# AM13E23019 register map
Vendor: Texas Instruments; File version: 1.0
CPU: CM33 r0p1, little endian, MPU, FPU, VTOR, 4 interrupt priority bits
Registers are 32-bit, read-write, reset 0x0 unless marked. A register's access mark holds for its fields unless they carry their own. Offsets are from the block's base; [hi:lo] are bit positions; {n}, {i} and the like mark numbered series.

## EQEP0 — EQEP module
Base 0x40448000
Same registers: EQEP1 0x40449000, EQEP2 0x4044A000
0x00 QPOSCNT access not given — Position Counter
0x04 QPOSINIT access not given — Position Counter Init
0x08 QPOSMAX access not given — Maximum Position Count
0x0C QPOSCMP access not given — Position Compare
0x10 QPOSILAT access not given — Index Position Latch
0x14 QPOSSLAT access not given — Strobe Position Latch
0x18 QPOSLAT access not given — Position Latch
0x1C QUTMR access not given — QEP Unit Timer
0x20 QUPRD access not given — QEP Unit Period
0x24 QWDTMR 16-bit access not given — QEP Watchdog Timer
0x26 QWDPRD 16-bit access not given — QEP Watchdog Period
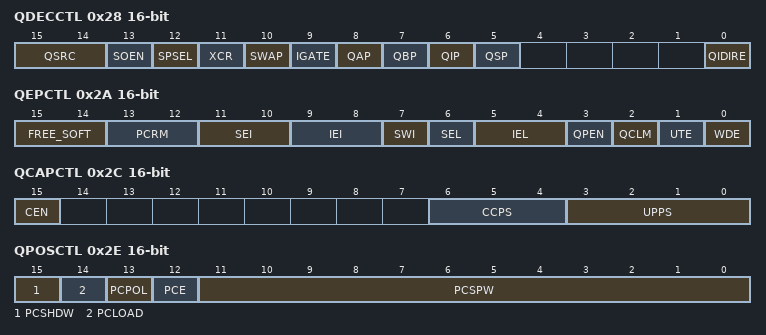
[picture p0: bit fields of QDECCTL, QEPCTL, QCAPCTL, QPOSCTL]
0x28 QDECCTL 16-bit — Quadrature Decoder Control
  [15:14] QSRC — Position-counter source selection
    0=QUAD_COUNT_MODE (Quadrature count mode (QCLK = iCLK, QDIR = iDIR)); 1=DIRECT_COUNT_MODE (Direction-count mode (QCLK = xCLK, QDIR = xDIR)); 2=UP_COUNT_MODE (UP count mode for frequency measurement (QCLK = xCLK, QDIR = 1)); 3=DOWN_COUNT_MODE (DOWN count mode for frequency measurement (QCLK = xCLK, QDIR = 0))
  [13] SOEN — Sync output-enable
    0=SYNC_DISABLE (Disable position-compare sync output); 1=SYNC_ENABLE (Enable position-compare sync output)
  [12] SPSEL — Sync output pin selection
    0=INDEX_PIN (Index pin is used for sync output); 1=STROBE_PIN (Strobe pin is used for sync output)
  [11] XCR — External Clock Rate
    0=XCR_2XRESOL (2x resolution: Count the rising/falling edge); 1=XCR_1XRESOL (1x resolution: Count the rising edge only)
  [10] SWAP — CLK/DIR Signal Source for Position Counter
    0=SWAP_DISABLE (Quadrature-clock inputs are not swapped); 1=SWAP_ENABLE (Quadrature-clock inputs are swapped)
  [9] IGATE — Index pulse gating option
    0=IGATE_DISABLE (Disable gating of Index pulse); 1=IGATE_ENABLE (Gate the index pin with strobe)
  [8] QAP — QEPA input polarity
    0=QAP_NOPOLAR (No effect); 1=QAP_POLAR (Negates QEPA input)
  [7] QBP — QEPB input polarity
    0=QBP_NOPOLAR (No effect); 1=QBP_POLAR (Negates QEPB input)
  [6] QIP — QEPI input polarity
    0=QIP_NOPOLAR (No effect); 1=QIP_POLAR (Negates QEPI input)
  [5] QSP — QEPS input polarity
    0=QSP_NOPOLAR (No effect); 1=QSP_POLAR (Negates QEPS input)
  [0] QIDIRE — Qep Index Direction Enhancement enable
0x2A QEPCTL 16-bit — QEP Control
  [15:14] FREE_SOFT — Emulation mode
    0=QPOSCNT behavior #br#Position counter stops immediately on emulation suspend #br#0h (R/W) = QWDTMR behavior #br#Watchdog counter stops immediately #br#0h (R/W) = QUTMR behavior #br#Unit timer stops immediately #br#0h (R/W) = QCTMR behavior #br#Capture Timer stops immediately; 1=QPOSCNT behavior #br#Position counter continues to count until the rollover #br#1h (R/W) = QWDTMR behavior #br#Watchdog counter counts until WD period match roll over #br#1h (R/W) = QUTMR behavior #br#Unit timer counts until period rollover #br#1h (R/W) = QCTMR behavior #br#Capture Timer counts until next unit period event; 2=QPOSCNT behavior #br#Position counter is unaffected by emulation suspend #br#2h (R/W) = QWDTMR behavior #br#Watchdog counter is unaffected by emulation suspend #br#2h (R/W) = QUTMR behavior #br#Unit timer is unaffected by emulation suspend #br#2h (R/W) = QCTMR behavior #br#Capture Timer is unaffected by emulation suspend; 3=Same as FREE_SOFT_2
  [13:12] PCRM — Postion counter reset
    0=PCRM_INDEX (Position counter reset on an index event); 1=PCRM_MAXPOS (Position counter reset on the maximum position); 2=PCRM_FIRSTINDEX (Position counter reset on the first index event); 3=PCRM_TIMEEVENT (Position counter reset on a unit time event)
  [11:10] SEI — Strobe event init
    0=SEI_NOTHING0 (Does nothing (action disabled)); 1=SEI_NOTHING1 (Does nothing (action disabled)); 2=SEI_INITQEPSRISING (Initializes the position counter on rising edge of the QEPS signal); 3=SEI_INITQEPSCLOCK (Clockwise Direction: #br#Initializes the position counter on the rising edge of QEPS strobe #br#Counter Clockwise Direction: #br#Initializes the position counter on the falling edge of QEPS strobe)
  [9:8] IEI — Index event init of position count
    0=IEI_NOTHING0 (Do nothing (action disabled)); 1=IEI_NOTHING1 (Do nothing (action disabled)); 2=IEI_INITRISING (Initializes the position counter on the rising edge of the QEPI signal (QPOSCNT = QPOSINIT)); 3=IEI_INITFALLING (Initializes the position counter on the falling edge of QEPI signal (QPOSCNT = QPOSINIT))
  [7] SWI — Software init position counter
    0=SWI_NOTHING (Do nothing (action disabled)); 1=SWI_INITPOS (Initialize position counter (QPOSCNT=QPOSINIT). This bit is not cleared automatically)
  [6] SEL — Strobe event latch
    0=SEL_QEPSRISING (The position counter is latched on the rising edge of QEPS strobe (QPOSSLAT = POSCCNT). Latching on the falling edge can be done by inverting the strobe input using the QSP bit in the QDECCTL register); 1=SEL_QEPSCLOCK (Clockwise Direction: #br#Position counter is latched on rising edge of QEPS strobe #br#Counter Clockwise Direction: #br#Position counter is latched on falling edge of QEPS strobe)
  [5:4] IEL — Index event latch
    0=IEL_RSVD (Reserved); 1=IEL_POSRISING (Latches position counter on rising edge of the index signal); 2=IEL_POSFALLING (Latches position counter on falling edge of the index signal); 3=IEL_SIM (Software index marker. Latches the position counter and quadrature direction flag on index event marker. The position counter is latched to the QPOSILAT register and the direction flag is latched in the QEPSTS[QDLF] bit. This mode is useful for software index marking.)
  [3] QPEN — Quadrature postotion counter enable
    0=QPEN_RESET (Reset the eQEP peripheral internal operating flags/read-only registers. Control/configuration registers are not disturbed by a software reset. #br#When QPEN is disabled, some flags in the QFLG register do not get reset or cleared and show the actual state of that flag.); 1=QPEN_ENABLE (eQEP position counter is enabled)
  [2] QCLM — QEP capture latch mode
    0=QCLM_CPU (Latch on position counter read by CPU. Capture timer and capture period values are latched into QCTMRLAT and QCPRDLAT registers when CPU reads the QPOSCNT register.); 1=QCLM_TIMEOUT (Latch on unit time out. Position counter, capture timer and capture period values are latched into QPOSLAT, QCTMRLAT and QCPRDLAT registers on unit time out.)
  [1] UTE — QEP unit timer enable
    0=UTE_DISABLE (Disable eQEP unit timer); 1=UTE_ENABLE (Enable unit timer)
  [0] WDE — QEP watchdog enable
    0=WDE_DISABLE (Disable the eQEP watchdog timer); 1=WDE_ENABLE (Enable the eQEP watchdog timer)
0x2C QCAPCTL 16-bit — Qaudrature Capture Control
  [15] CEN — Enable eQEP capture
    0=CEN_DISABLE (eQEP capture unit is disabled); 1=CEN_ENABLE (eQEP capture unit is enabled)
  [6:4] CCPS — eQEP capture timer clock prescaler
    0=SYSCLKOUT1 (CAPCLK = SYSCLKOUT/1); 1=SYSCLKOUT2 (CAPCLK = SYSCLKOUT/2); 2=SYSCLKOUT4 (CAPCLK = SYSCLKOUT/4); 3=SYSCLKOUT8 (CAPCLK = SYSCLKOUT/8); 4=SYSCLKOUT16 (CAPCLK = SYSCLKOUT/16); 5=SYSCLKOUT32 (CAPCLK = SYSCLKOUT/32); 6=SYSCLKOUT64 (CAPCLK = SYSCLKOUT/64); 7=SYSCLKOUT128 (CAPCLK = SYSCLKOUT/128)
  [3:0] UPPS — Unit position event prescaler
    0=QCLK1 (UPEVNT = QCLK/1); 1=QCLK2 (UPEVNT = QCLK/2); 2=QCLK4 (UPEVNT = QCLK/4); 3=QCLK8 (UPEVNT = QCLK/8); 4=QCLK16 (UPEVNT = QCLK/16); 5=QCLK32 (UPEVNT = QCLK/32); 6=QCLK64 (UPEVNT = QCLK/64); 7=QCLK128 (UPEVNT = QCLK/128); 8=QCLK256 (UPEVNT = QCLK/256); 9=QCLK512 (UPEVNT = QCLK/512); 10=QCLK1024 (UPEVNT = QCLK/1024); 11=QCLK2048 (UPEVNT = QCLK/2048); {v}=QCLK_RSVD{v-12} (Reserved) (v=12..15)
0x2E QPOSCTL 16-bit — Position Compare Control
  [15] PCSHDW — Position compare of shadow enable
    0=PCSHDW_DISABLE (Shadow disabled, load Immediate); 1=PCSHDW_ENABLE (Shadow enabled)
  [14] PCLOAD — Position compare of shadow load
    0=Load on QPOSCNT = 0; 1=PCLOAD_QPOSCMP (Load when QPOSCNT = QPOSCMP)
  [13] PCPOL — Polarity of sync output
    0=PCPOL_HIGH (Active HIGH pulse output); 1=PCPOL_LOW (Active LOW pulse output)
  [12] PCE — Position compare enable/disable
    0=PCE_DISABLE (Disable position compare unit); 1=PCE_ENABLE (Enable position compare unit)
  [11:0] PCSPW — Position compare sync pulse width
    0=SYSCLKOUT4 (1 * 4 * SYSCLKOUT cycles); 1=SYSCLKOUT8 (2 * 4 * SYSCLKOUT cycles); 0xFFF=SYSCLKOUT16384 (4096 * 4 * SYSCLKOUT cycles)
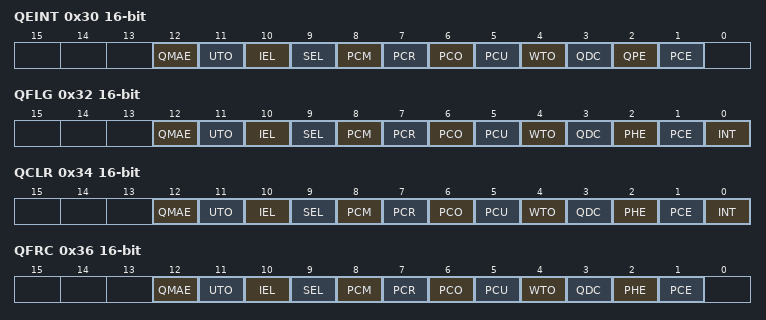
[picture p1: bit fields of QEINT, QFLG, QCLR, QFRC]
0x30 QEINT 16-bit — QEP Interrupt Control
  [12] QMAE — QMA error interrupt enable
    0=QMAE_DISABLE (Interrupt is disabled); 1=QMAE_ENABLE (Interrupt is enabled)
  [11] UTO — Unit time out interrupt enable
    0=UTO_DISABLE (Interrupt is disabled); 1=UTO_ENABLE (Interrupt is enabled)
  [10] IEL — Index event latch interrupt enable
    0=IEL_DISABLE (Interrupt is disabled); 1=IEL_ENABLE (Interrupt is enabled)
  [9] SEL — Strobe event latch interrupt enable
    0=SEL_DISABLE (Interrupt is disabled); 1=SEL_ENABLE (Interrupt is enabled)
  [8] PCM — Position-compare match interrupt enable
    0=PCM_DISABLE (Interrupt is disabled); 1=PCM_ENABLE (Interrupt is enabled)
  [7] PCR — Position-compare ready interrupt enable
    0=PCR_DISABLE (Interrupt is disabled); 1=PCR_ENABLE (Interrupt is enabled)
  [6] PCO — Position counter overflow interrupt enable
    0=PCO_DISABLE (Interrupt is disabled); 1=PCO_ENABLE (Interrupt is enabled)
  [5] PCU — Position counter underflow interrupt enable
    0=PCU_DISABLE (Interrupt is disabled); 1=PCU_ENABLE (Interrupt is enabled)
  [4] WTO — Watchdog time out interrupt enable
    0=WTO_DISABLE (Interrupt is disabled); 1=WTO_ENABLE (Interrupt is enabled)
  [3] QDC — Quadrature direction change interrupt enable
    0=QDC_DISABLE (Interrupt is disabled); 1=QDC_ENABLE (Interrupt is enabled)
  [2] QPE — Quadrature phase error interrupt enable
    0=QPE_DISABLE (Interrupt is disabled); 1=QPE_ENABLE (Interrupt is enabled)
  [1] PCE — Position counter error interrupt enable
    0=PCE_DISABLE (Interrupt is disabled); 1=PCE_ENABLE (Interrupt is enabled)
0x32 QFLG 16-bit ro — QEP Interrupt Flag
  [12] QMAE — QMA error interrupt flag
    0=QMAE_NOFLAG (No interrupt generated); 1=QMAE_FLAG (Interrupt was generated)
  [11] UTO — Unit time out interrupt flag
    0=UTO_NOFLAG (No interrupt generated); 1=UTO_FLAG (Set by eQEP unit timer period match)
  [10] IEL — Index event latch interrupt flag
    0=IEL_NOFLAG (No interrupt generated); 1=IEL_FLAG (This bit is set after latching the QPOSCNT to QPOSILAT)
  [9] SEL — Strobe event latch interrupt flag
    0=SEL_NOFLAG (No interrupt generated); 1=SEL_FLAG (This bit is set after latching the QPOSCNT to QPOSSLAT)
  [8] PCM — eQEP compare match event interrupt flag
    0=PCM_NOFLAG (No interrupt generated); 1=PCM_FLAG (This bit is set on position-compare match)
  [7] PCR — Position-compare ready interrupt flag
    0=PCR_NOFLAG (No interrupt generated); 1=PCR_FLAG (This bit is set after transferring the shadow register value to the active position compare register)
  [6] PCO — Position counter overflow interrupt flag
    0=PCO_NOFLAG (No interrupt generated); 1=PCO_FLAG (This bit is set on position counter overflow.)
  [5] PCU — Position counter underflow interrupt flag
    0=PCU_NOFLAG (No interrupt generated); 1=PCU_FLAG (This bit is set on position counter underflow.)
  [4] WTO — Watchdog timeout interrupt flag
    0=WTO_NOFLAG (No interrupt generated); 1=WTO_FLAG (Set by watchdog timeout)
  [3] QDC — Quadrature direction change interrupt flag
    0=QDC_NOFLAG (No interrupt generated); 1=QDC_FLAG (Interrupt was generated)
  [2] PHE — Quadrature phase error interrupt flag
    0=PHE_NOFLAG (No interrupt generated); 1=PHE_FLAG (Set on simultaneous transition of QEPA and QEPB)
  [1] PCE — Position counter error interrupt flag
    0=PCE_NOFLAG (No interrupt generated); 1=PCE_FLAG (Position counter error)
  [0] INT — Global interrupt status flag
    0=INT_NOFLAG (No interrupt generated); 1=INT_FLAG (Interrupt was generated)
0x34 QCLR 16-bit — QEP Interrupt Clear
  [12] QMAE — Clear QMA error interrupt flag
    0=QMAE_NOEFFECT (No effect); 1=QMAE_CLR (Clears the interrupt flag)
  [11] UTO — Clear unit time out interrupt flag
    0=UTO_NOEFFECT (No effect); 1=UTO_CLR (Clears the interrupt flag)
  [10] IEL — Clear index event latch interrupt flag
    0=IEL_NOEFFECT (No effect); 1=IEL_CLR (Clears the interrupt flag)
  [9] SEL — Clear strobe event latch interrupt flag
    0=SEL_NOEFFECT (No effect); 1=SEL_CLR (Clears the interrupt flag)
  [8] PCM — Clear eQEP compare match event interrupt flag
    0=PCM_NOEFFECT (No effect); 1=PCM_CLR (Clears the interrupt flag)
  [7] PCR — Clear position-compare ready interrupt flag
    0=PCR_NOEFFECT (No effect); 1=PCR_CLR (Clears the interrupt flag)
  [6] PCO — Clear position counter overflow interrupt flag
    0=PCO_NOEFFECT (No effect); 1=PCO_CLR (Clears the interrupt flag)
  [5] PCU — Clear position counter underflow interrupt flag
    0=PCU_NOEFFECT (No effect); 1=PCU_CLR (Clears the interrupt flag)
  [4] WTO — Clear watchdog timeout interrupt flag
    0=WTO_NOEFFECT (No effect); 1=WTO_CLR (Clears the interrupt flag)
  [3] QDC — Clear quadrature direction change interrupt flag
    0=QDC_NOEFFECT (No effect); 1=QDC_CLR (Clears the interrupt flag)
  [2] PHE — Clear quadrature phase error interrupt flag
    0=PHE_NOEFFECT (No effect); 1=PHE_CLR (Clears the interrupt flag)
  [1] PCE — Clear position counter error interrupt flag
    0=PCE_NOEFFECT (No effect); 1=PCE_CLR (Clears the interrupt flag)
  [0] INT — Global interrupt clear flag
    0=INT_NOEFFECT (No effect); 1=INT_CLR (Clears the interrupt flag)
0x36 QFRC 16-bit — QEP Interrupt Force
  [12] QMAE — Force QMA error interrupt
    0=QMAE_NOEFFECT (No effect); 1=QMAE_FORCE (Force the interrupt)
  [11] UTO — Force unit time out interrupt
    0=UTO_NOEFFECT (No effect); 1=UTO_FORCE (Force the interrupt)
  [10] IEL — Force index event latch interrupt
    0=IEL_NOEFFECT (No effect); 1=IEL_FORCE (Force the interrupt)
  [9] SEL — Force strobe event latch interrupt
    0=SEL_NOEFFECT (No effect); 1=SEL_FORCE (Force the interrupt)
  [8] PCM — Force position-compare match interrupt
    0=PCM_NOEFFECT (No effect); 1=PCM_FORCE (Force the interrupt)
  [7] PCR — Force position-compare ready interrupt
    0=PCR_NOEFFECT (No effect); 1=PCR_FORCE (Force the interrupt)
  [6] PCO — Force position counter overflow interrupt
    0=PCO_NOEFFECT (No effect); 1=PCO_FORCE (Force the interrupt)
  [5] PCU — Force position counter underflow interrupt
    0=PCU_NOEFFECT (No effect); 1=PCU_FORCE (Force the interrupt)
  [4] WTO — Force watchdog time out interrupt
    0=WTO_NOEFFECT (No effect); 1=WTO_FORCE (Force the interrupt)
  [3] QDC — Force quadrature direction change interrupt
    0=QDC_NOEFFECT (No effect); 1=QDC_FORCE (Force the interrupt)
  [2] PHE — Force quadrature phase error interrupt
    0=PHE_NOEFFECT (No effect); 1=PHE_FORCE (Force the interrupt)
  [1] PCE — Force position counter error interrupt
    0=PCE_NOEFFECT (No effect); 1=PCE_FORCE (Force the interrupt)
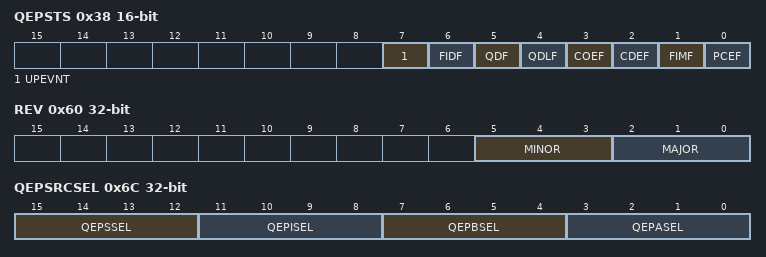
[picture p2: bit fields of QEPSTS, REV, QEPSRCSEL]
0x38 QEPSTS 16-bit access per field — QEP Status
  [7] UPEVNT rw — Unit position event flag
    0=UPEVNT_NODETCT (No unit position event detected); 1=UPEVNT_DETCT (Unit position event detected. Write 1 to clear)
  [6] FIDF ro — The first index marker
    0=FIDF_COUNTERCLK (Counter-clockwise rotation (or reverse movement) on the first index event); 1=FIDF_CLK (Clockwise rotation (or forward movement) on the first index event)
  [5] QDF ro — Quadrature direction flag
    0=QDF_COUNTERCLK (Counter-clockwise rotation (or reverse movement)); 1=QDF_CLK (Clockwise rotation (or forward movement))
  [4] QDLF ro — eQEP direction latch flag
    0=QDLF_COUNTERCLK (Counter-clockwise rotation (or reverse movement) on index event marker); 1=QDLF_CLK (Clockwise rotation (or forward movement) on index event marker)
  [3] COEF rw — Capture overflow error flag
    0=COEF_WRT1 (Overflow has not occurred.); 1=COEF_OVF (Overflow occurred in eQEP Capture timer (QEPCTMR). This bit is cleared by writing a '1'.)
  [2] CDEF rw — Capture direction error flag
    0=CDEF_WRT1 (Capture direction error has not occurred.); 1=CDEF_DIRECT (Direction change occurred between the capture position event. This bit is cleared by writing a '1'.)
  [1] FIMF rw — First index marker flag
    0=FIMF_WRT1 (First index pulse has not occurred.); 1=FIMF_SETINDEX (Set by first occurrence of index pulse. This bit is cleared by writing a '1'.)
  [0] PCEF ro — Position counter error flag.
    0=PCEF_NOERROR (No error occurred during the last index transition); 1=PCEF_ERROR (Position counter error)
0x3A QCTMR 16-bit access not given — QEP Capture Timer
0x3C QCPRD 16-bit access not given — QEP Capture Period
0x3E QCTMRLAT 16-bit access not given — QEP Capture Latch
0x40 QCPRDLAT 16-bit access not given — QEP Capture Period Latch
0x60 REV ro — QEP Revision Number
  [5:3] MINOR — Minor Revision Number
  [2:0] MAJOR — Major Revision Number
0x64 QEPSTROBESEL — QEP Strobe select register
  [1:0] STROBESEL — QMA Mode Select
    0=QS_AFTER_POL_MUX (QEP Strobe after polarity mux); 2=ADCSOCA_AS_QS (QEP Strobe after polarity mux ORed with ADCSOCA); 3=ADCSOCB_AS_QS (QEP Strobe after polarity mux ORed with ADCSOCB)
0x68 QMACTRL — QMA Control register
  [2:0] MODE — QMA Mode Select
0x6C QEPSRCSEL — QEP Source Select Register
  [15:12] QEPSSEL — QEPS Source select
  [11:8] QEPISEL — QEPI Source select
  [7:4] QEPBSEL — QEPB Source select
  [3:0] QEPASEL — QEPA Source select
